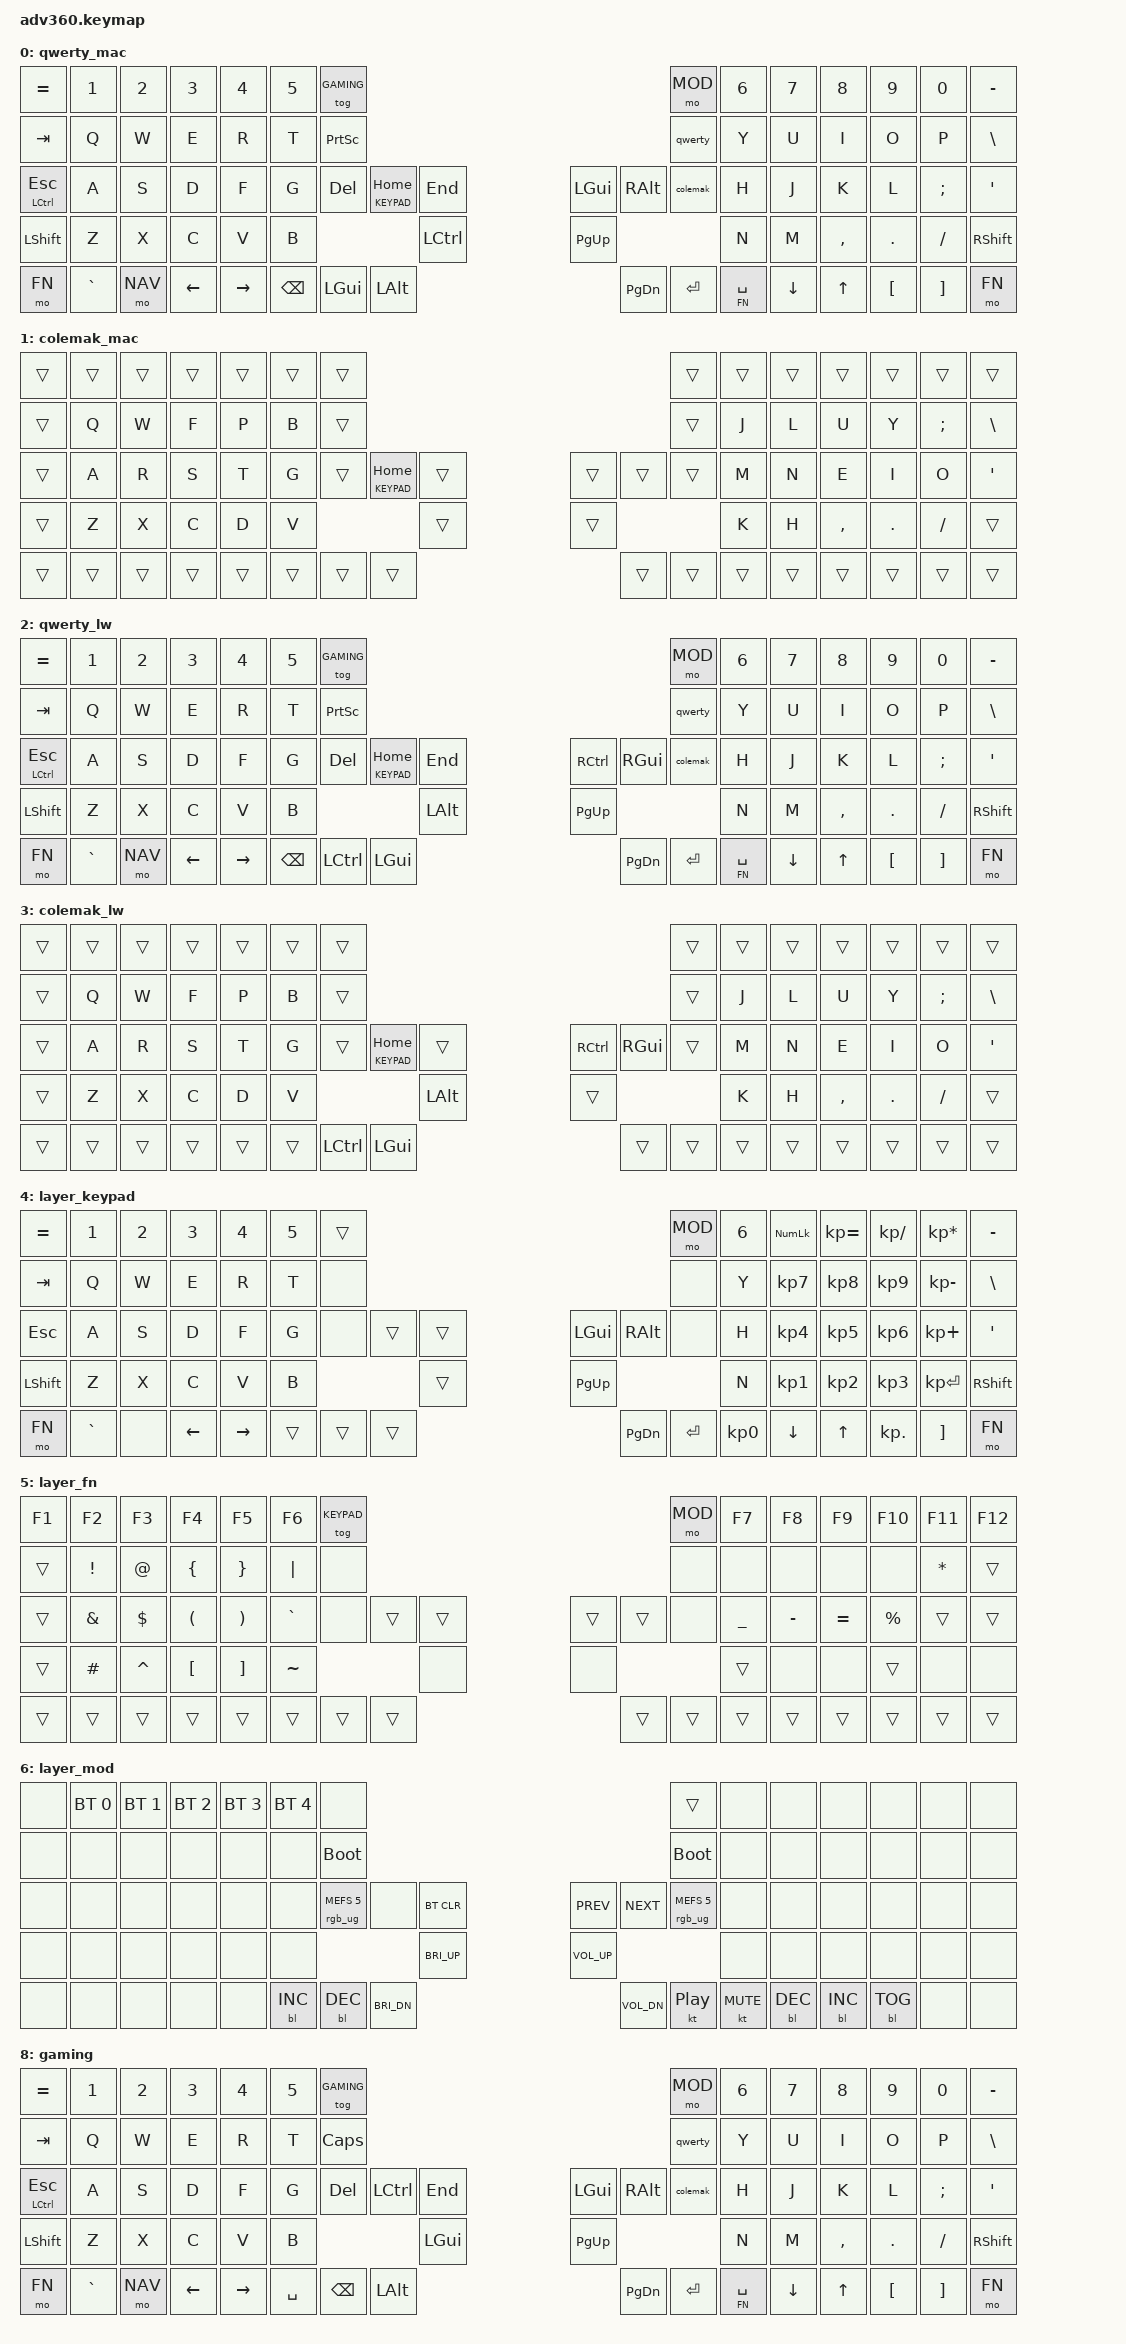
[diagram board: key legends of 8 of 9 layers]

/*
 * Copyright (c) 2020 The ZMK Contributors
 *
 * SPDX-License-Identifier: MIT
 */


/* THIS FILE WAS GENERATED!
 *
 * This file was generated automatically. You may or may not want to
 * edit it directly.
 */

#include <behaviors.dtsi>
#include <dt-bindings/zmk/keys.h>
#include <dt-bindings/zmk/bt.h>
#include <dt-bindings/zmk/rgb.h>
#include <dt-bindings/zmk/backlight.h>
#include <dt-bindings/zmk/keys.h>

#define HYP(key) LS(LC(LA(LG(key))))
#define HYPER    LS(LC(LA(LGUI)))


#define KEYS_LEFT 0 1 2 3 4 5 6 \
                  14 15 16 17 18 19 20 \
                  28 29 30 31 32 33 34 \
                  46 47 48 49 50 51 \
                  66 67 68 69 70

#define KEYS_RIGHT 7 8 9 10 11 12 13 \
                   21 22 23 24 25 26 27 \
                   39 40 41 42 43 44 45 \
                   60 61 62 63 64 65 \
                   77 78 79 80 81

#define THUMBS_LEFT 35 36 54 71 72 73

#define THUMBS_RIGHT 37 38 57 74 75 76

#define THUMBS THUMBS_LEFT THUMBS_RIGHT


#define MACLOCK  LG(LC(Q))
#define ___ &trans

#define QWERTY_M 0 // QWERTY_MAC
#define COLEMAK_M 1 // COLEMAK_MAC
#define QWERTY_LW 2 // QWERTY Linux/Windows
#define COLEMAK_LW 3 // Colemak Linux/Windows
#define KEYPAD 4
#define FN 5
#define MOD 6
#define NAV 7
#define GAMING 8

&lt {
    quick-tap-ms = <150>;
    global-quick-tap;
};


/ {
    behaviors {
      #include "macros.dtsi"
      #include "version.dtsi"
      #ifndef VERSION_MACRO
      macro_ver: macro_ver {
        compatible = "zmk,behavior-macro";
        label = "macro_version";
        #binding-cells = <0>;
        bindings = <&kp RET>;
      };
      #endif

    hm: homerow_mods {
        compatible = "zmk,behavior-hold-tap";
        label = "HOMEROW_MODS";
        #binding-cells = <2>;
        tapping-term-ms = <200>;
        quick_tap_ms = <175>;
        #flavor = "tap-preferred";
        flavor = "balanced";
        bindings = <&kp>, <&kp>;
    };

    hm_l: homerow_mods_left {
        compatible = "zmk,behavior-hold-tap";
        label = "HOMEROW_MODS_LEFT";
        #binding-cells = <2>;
        tapping-term-ms = <200>;
        quick_tap_ms = <175>;
        flavor = "balanced";
        bindings = <&kp>, <&kp>;
        hold-trigger-key-positions = <KEYS_RIGHT THUMBS>;
    };

    hm_r: homerow_mods_right {
        compatible = "zmk,behavior-hold-tap";
        label = "HOMEROW_MODS_RIGHT";
        #binding-cells = <2>;
        tapping-term-ms = <200>;
        quick_tap_ms = <175>;
        flavor = "balanced";
        bindings = <&kp>, <&kp>;
        hold-trigger-key-positions = <KEYS_LEFT THUMBS>;
    };
  };

  /* The following two provide the ability for shifting into OS specific layout
  *  config.
  *
  * - Ctrl and Meta are switched when moving from Mac to Linux/Windows modes
  */
   qwerty: qwerty_os_toggle {
        compatible = "zmk,behavior-mod-morph";
        label = "QWERTY_TOGGLE";
        #binding-cells = <0>;
        bindings = <&to QWERTY_M>, <&to QWERTY_LW>;
        mods = <(MOD_LSFT|MOD_RSFT)>;
    };


   colemak: colemak_os_toggle {
        compatible = "zmk,behavior-mod-morph";
        label = "COLEMAK_TOGGLE";
        #binding-cells = <0>;
        bindings = <&to COLEMAK_M>, <&to COLEMAK_LW>;
        mods = <(MOD_LSFT|MOD_RSFT)>;
    };

    // Home row mods (MAC - COLEMAK)
    #define _T_SFT &hm_l LSHFT T  // Shift on index fingers
    #define _N_SFT &hm_r RSHFT N
    #define _S_CMD &hm_l LGUI S   // Command on middle fingers
    #define _E_CMD &hm_r RGUI E
    #define _A_CTL &hm_l LCTRL A  // Control on pinky
    #define _O_CTL &hm_r RCTRL O
    #define _R_OPT &hm_l LALT R   // Option on ring finger
    #define _I_OPT &hm_r RALT I

    // Home row mods (Windows/Linux - COLEMAK)
    #define _T_SFT &hm_l LSHFT T  // Shift on index fingers
    #define _N_SFT &hm_r RSHFT N
    #define _S_GUI &hm_l LGUI S   // GUI on middle fingers (used for layer changing)
    #define _E_GUI &hm_r RGUI E
    #define _A_CTL &hm_l LCTRL A  // Control on pinky (used for copy/paste)
    #define _O_CTL &hm_r RCTRL O
    #define _R_ALT &hm_l LALT R   // Alt on ring finger
    #define _I_ALT &hm_r RALT I

    // MacOS shortcuts
    #define _1PASS &kp LG(BSLH)      // 1Password
    #define _APEX  &kp LC(UP)        // App exposé
    #define _FQUIT &kp LA(LG(ESC))   // Force quit
    #define _MCTL  &kp LC(UP)      // Mission control
    #define _SCRNS &kp LG(LS(N4))    // Screenshot
    #define _EMOJI &kp LC(LG(SPACE)) // Emoji picker
    #define _NEXTS &kp LC(RIGHT)     // Next screen
    #define _PREVS &kp LC(LEFT)      // Previous screen

    keymap {
        compatible = "zmk,keymap";


        qwerty_mac {
            bindings = <
        &kp EQUAL      &kp N1  &kp N2    &kp N3     &kp N4  &kp N5     &tog GAMING                                                                                &mo MOD        &kp N6  &kp N7     &kp N8    &kp N9  &kp N0    &kp MINUS
        &kp TAB        &kp Q   &kp W     &kp E      &kp R   &kp T      &kp PSCRN                                                                                   &qwerty        &kp Y   &kp U      &kp I     &kp O   &kp P     &kp BSLH
        &mt LCTRL ESC  &kp A   &kp S     &kp D      &kp F   &kp G      &kp DEL       &lt KEYPAD HOME &kp END                       &kp LGUI     &kp RALT          &colemak       &kp H   &kp J      &kp K     &kp L   &kp SEMI  &kp SQT
        &kp LSHFT      &kp Z   &kp X     &kp C      &kp V   &kp B                                    &kp LCTRL                     &kp PG_UP                                     &kp N   &kp M      &kp COMMA &kp DOT &kp FSLH  &kp RSHFT
        &mo FN         &kp GRAVE &mo NAV   &kp LEFT   &kp RIGHT        &kp BACKSPACE &kp LEFT_GUI    &kp LEFT_ALT                  &kp PG_DN &kp ENTER  &lt FN SPACE                       &kp DOWN   &kp UP    &kp LBKT &kp RBKT  &mo FN
            >;
        };

        colemak_mac {
            bindings = <
        &trans         &trans  &trans    &trans     &trans  &trans     &trans                                                                                     &trans         &trans  &trans     &trans    &trans  &trans    &trans
        &trans         &kp Q   &kp W     &kp F      &kp P   &kp B      &trans                                                                                     &trans         &kp J   &kp L      &kp U     &kp Y   &kp SEMI  &kp BSLH
        &trans         &kp A   &kp R     &kp S      &kp T   &kp G      &trans      &lt KEYPAD HOME &trans                        &trans    &trans               &trans         &kp M   &kp N      &kp E     &kp I   &kp O     &kp SQT
        &trans         &kp Z   &kp X     &kp C      &kp D   &kp V                                    &trans                        &trans                                        &kp K   &kp H      &kp COMMA &kp DOT &kp FSLH  &trans
        &trans         &trans  &trans    &trans     &trans             &trans          &trans        &trans                        &trans    &trans     &trans                           &trans     &trans    &trans  &trans    &trans
            >;
        };

        qwerty_lw {
            bindings = <
        &kp EQUAL      &kp N1  &kp N2    &kp N3     &kp N4  &kp N5     &tog GAMING                                                                                &mo MOD    &kp N6  &kp N7     &kp N8    &kp N9  &kp N0    &kp MINUS
        &kp TAB        &kp Q   &kp W     &kp E      &kp R   &kp T      &kp PSCRN                                                                                   &qwerty    &kp Y   &kp U      &kp I     &kp O   &kp P     &kp BSLH
        &mt LCTRL ESC  &kp A   &kp S     &kp D      &kp F   &kp G      &kp DEL       &lt KEYPAD HOME &kp END                   &kp RCTRL        &kp RGUI          &colemak   &kp H   &kp J      &kp K     &kp L   &kp SEMI  &kp SQT
        &kp LSHFT      &kp Z   &kp X     &kp C      &kp V   &kp B                                    &kp LALT                  &kp PG_UP                                     &kp N   &kp M      &kp COMMA &kp DOT &kp FSLH  &kp RSHFT
        &mo FN         &kp GRAVE &mo NAV  &kp LEFT   &kp RIGHT         &kp BACKSPACE &kp LCTRL       &kp LGUI                  &kp PG_DN     &kp ENTER  &lt FN SPACE                 &kp DOWN   &kp UP    &kp LBKT &kp RBKT  &mo FN
            >;
        };

        colemak_lw {
            bindings = <
        &trans         &trans  &trans    &trans     &trans  &trans     &trans                                                                                     &trans         &trans  &trans     &trans    &trans  &trans    &trans
        &trans         &kp Q   &kp W     &kp F      &kp P   &kp B      &trans                                                                                     &trans         &kp J   &kp L      &kp U     &kp Y   &kp SEMI  &kp BSLH
        &trans         &kp A   &kp R     &kp S      &kp T   &kp G      &trans      &lt KEYPAD HOME &trans                          &kp RCTRL &kp RGUI           &trans         &kp M   &kp N      &kp E     &kp I   &kp O     &kp SQT
        &trans         &kp Z   &kp X     &kp C      &kp D   &kp V                                    &kp LALT                        &trans                                      &kp K   &kp H      &kp COMMA &kp DOT &kp FSLH  &trans
        &trans         &trans  &trans    &trans     &trans             &trans          &kp LCTRL     &kp LGUI                        &trans    &trans     &trans                         &trans     &trans    &trans  &trans    &trans
            >;
        };

        layer_keypad {
            bindings = <
        &kp EQUAL      &kp N1  &kp N2    &kp N3     &kp N4  &kp N5     &trans                                                                                     &mo MOD     &kp N6  &kp KP_NUM &kp KP_EQUAL &kp KP_DIVIDE  &kp KP_MULTIPLY  &kp MINUS
        &kp TAB        &kp Q   &kp W     &kp E      &kp R   &kp T      &none                                                                                      &none          &kp Y   &kp KP_N7  &kp KP_N8 &kp KP_N9 &kp KP_MINUS   &kp BSLH
        &kp ESC        &kp A   &kp S     &kp D      &kp F   &kp G      &none           &trans        &trans                        &kp LGUI  &kp RALT             &none          &kp H   &kp KP_N4  &kp KP_N5 &kp KP_N6 &kp KP_PLUS    &kp SQT
        &kp LSHFT      &kp Z   &kp X     &kp C      &kp V   &kp B                                    &trans                        &kp PG_UP                                     &kp N   &kp KP_N1  &kp KP_N2 &kp KP_N3 &kp KP_ENTER   &kp RSHFT
        &mo FN       &kp GRAVE &none     &kp LEFT  &kp RIGHT           &trans          &trans        &trans                        &kp PG_DN &kp ENTER  &kp KP_N0                        &kp DOWN   &kp UP    &kp KP_DOT &kp RBKT      &mo FN
            >;
        };

        layer_fn {
            bindings = <
        &kp F1         &kp F2  &kp F3    &kp F4     &kp F5  &kp F6     &tog KEYPAD                                                                                &mo MOD        &kp F7   &kp F8    &kp F9    &kp F10 &kp F11   &kp F12
        &trans         &kp EXCL &kp AT   &kp LBRC   &kp RBRC &kp PIPE  &none                                                                                      &none          &none    &none     &none     &none   &kp ASTERISK &trans
        &trans         &kp AMPS &kp DOLLAR &kp LPAR &kp RPAR &kp GRAVE &none           &trans        &trans                        &trans    &trans               &none          &kp UNDER &kp MINUS &kp EQUAL &kp PERCENT &trans &trans
        &trans         &kp HASH &kp CARET &kp LBKT  &kp RBKT &kp TILDE                                &none                        &none                                         &trans   &none     &none     &trans  &none     &none
        &trans         &trans  &trans    &trans     &trans  &trans     &trans          &trans        &trans                        &trans    &trans     &trans                            &trans    &trans    &trans  &trans
            >;

        };

        layer_mod {
            bindings = <
            &none          &bt BT_SEL 0  &bt BT_SEL 1  &bt BT_SEL 2  &bt BT_SEL 3  &bt BT_SEL 4  &none                                                                                           &trans                   &none       &none       &none       &none   &none   &none
            &none          &none         &none         &none         &none         &none         &bootloader                                                                                     &bootloader              &none       &none       &none       &none   &none   &none
            &none          &none         &none         &none         &none         &none         &rgb_ug RGB_MEFS_CMD 5             &none  &bt BT_CLR             &kp C_PREV    &kp C_NEXT       &rgb_ug RGB_MEFS_CMD 5   &none       &none       &none       &none   &none   &none
            &none          &none         &none         &none         &none         &none                                                   &kp C_BRI_UP           &kp C_VOL_UP                                            &none       &none       &none       &none   &none   &none
            &none          &none         &none         &none         &none                                         &bl BL_INC  &bl BL_DEC  &kp C_BRI_DN           &kp C_VOL_DN  &kt C_PLAY_PAUSE &kt C_MUTE                           &bl BL_DEC  &bl BL_INC  &bl BL_TOG &none &none
            >;
        };

        nav {
            bindings = <
            &none          &none         &none         &none         &none         &none         &none                                                           &none       &none       &none       &none       &none   &none   &none
            &none          &none         &none         &none         &none         &none         &none                                                           &none       &kp LEFT    &kp DOWN    &kp UP      &kp RIGHT &none   &none
            &trans         &none         &none         &none         &none         &none         &none      &none     &none            &none       &none          &none       &kp H       &kp J       &kp K       &kp L   &none   &none
            &trans         &none         &none         &none         &none         &none                              &trans           &none                                  &none       &none       &none       &none   &none   &none
            &none          &none         &none         &none         &none                       &trans     &trans    &trans           &none       &none          &none                   &none       &none       &none &none
            >;
        };

        gaming {
            bindings = <
        &kp EQUAL      &kp N1  &kp N2    &kp N3     &kp N4  &kp N5     &tog GAMING                                                                                &mo MOD        &kp N6  &kp N7     &kp N8    &kp N9  &kp N0    &kp MINUS
        &kp TAB        &kp Q   &kp W     &kp E      &kp R   &kp T      &kp CAPS                                                                                   &qwerty        &kp Y   &kp U      &kp I     &kp O   &kp P     &kp BSLH
        &mt LCTRL ESC  &kp A   &kp S     &kp D      &kp F   &kp G      &kp DEL   &kp LCTRL                &kp END                       &kp LGUI     &kp RALT          &colemak       &kp H   &kp J      &kp K     &kp L   &kp SEMI  &kp SQT
        &kp LSHFT      &kp Z   &kp X     &kp C      &kp V   &kp B                                         &kp LGUI                     &kp PG_UP                                     &kp N   &kp M      &kp COMMA &kp DOT &kp FSLH  &kp RSHFT
        &mo FN         &kp GRAVE &mo NAV   &kp LEFT   &kp RIGHT        &kp SPACE &kp BACKSPACE            &kp LALT                  &kp PG_DN &kp ENTER  &lt FN SPACE                       &kp DOWN   &kp UP    &kp LBKT &kp RBKT  &mo FN
            >;
        };
    };
};
